# LOCKDEMO register map
Registers are 32-bit, access not given, reset 0x0 unless marked. A register's access mark holds for its fields unless they carry their own. Offsets are from the block's base; lines under a group give offsets from that group; [hi:lo] are bit positions; {n}, {i} and the like mark numbered series; 'fields as' and 'values as' point back to an identical list; <NAME> marks a mode.

## Memory map
0x1FFF7800 OTP size 0x20 — One-time-programmable fuses
0x1FFF7A10 UID size 0xC — Unique device identifier
0x40013000 SPI1 size 0x400 — Serial peripheral interface
0x40022000 FLASHC size 0x400 — Flash controller and option bytes
0x50060800 RNG size 0x400 — Random number generator

## FLASHC — Flash controller and option bytes
Base 0x40022000
0x00 ACR
0x04 KEYR wo — Flash unlock key
0x08 OPTKEYR wo — Option bytes unlock key
0x0C SR
  [0] BSY
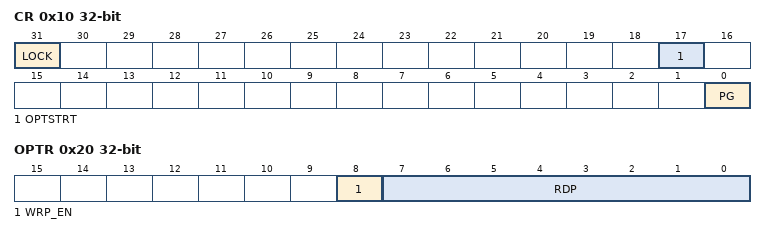
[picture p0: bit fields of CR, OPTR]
0x10 CR
  [31] LOCK, [17] OPTSTRT, [0] PG
0x20 OPTR — Option bytes
  [8] WRP_EN — Write protection enable
  [7:0] RDP — Readout protection level

## UID — Unique device identifier
Base 0x1FFF7A10
{0x0+4i} UID{i} (i=0..2) ro

## OTP — One-time-programmable fuses
Base 0x1FFF7800
{0x0+4i} VERCNT[{i}] (i=0..3) ro — Version counter
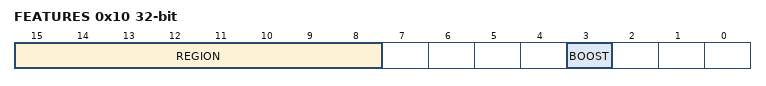
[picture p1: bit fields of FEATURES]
0x10 FEATURES ro
  [15:8] REGION, [3] BOOST

## RNG — Random number generator
Base 0x50060800
0x00 CR
0x04 SR
0x08 DR ro

## SPI1 — Serial peripheral interface
Base 0x40013000
0x00 CR1
0x08 SR
0x0C DR

## Notices in the file
SPDX-License-Identifier: Apache-2.0
